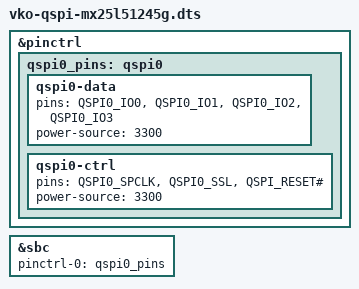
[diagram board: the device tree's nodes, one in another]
/*
 * Copyright 2024 Vekatech
 *
 * This program is free software; you can redistribute it and/or
 * modify it under the terms of the GNU General Public License
 * as published by the Free Software Foundation; either version 2
 * of the License, or (at your option) any later version.
 *
 * This program is distributed in the hope that it will be useful,
 * but WITHOUT ANY WARRANTY; without even the implied warranty of
 * MERCHANTABILITY or FITNESS FOR A PARTICULAR PURPOSE. See the
 * GNU General Public License for more details.
 */

/dts-v1/;
/plugin/;

#include <dt-bindings/pinctrl/rzg2l-pinctrl.h>

&pinctrl {
	qspi0_pins: qspi0 {
		qspi0-data {
			pins = "QSPI0_IO0", "QSPI0_IO1", "QSPI0_IO2", "QSPI0_IO3";
			power-source = <3300>;
		};

		qspi0-ctrl {
			pins = "QSPI0_SPCLK", "QSPI0_SSL", "QSPI_RESET#";
			power-source = <3300>;
		};
	};
};

&sbc {
	pinctrl-0 = <&qspi0_pins>;
	pinctrl-names = "default";

	status = "okay";
};
